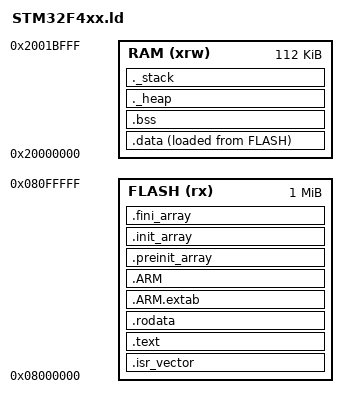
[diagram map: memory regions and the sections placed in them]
/* STM32F4xx Linker Script
 * Target: STM32F407VGTx
 * Flash: 1MB @ 0x08000000
 * SRAM1: 112KB @ 0x20000000
 * SRAM2: 16KB  @ 0x2001C000
 */

/* Entry Point */
ENTRY(Reset_Handler)

/* Highest address of the user mode stack */
_estack = 0x2001C000;    /* end of SRAM1 */

/* Minimum required sizes */
_Min_Heap_Size  = 0x200;   /* 512 bytes */
_Min_Stack_Size = 0x400;   /* 1024 bytes */

/* Memory Areas */
MEMORY
{
  FLASH (rx)  : ORIGIN = 0x08000000, LENGTH = 1024K
  RAM   (xrw) : ORIGIN = 0x20000000, LENGTH = 112K
}

SECTIONS
{
  /* Vector table at start of Flash */
  .isr_vector :
  {
    . = ALIGN(4);
    KEEP(*(.isr_vector))
    . = ALIGN(4);
  } >FLASH

  /* Code and read-only data */
  .text :
  {
    . = ALIGN(4);
    *(.text)
    *(.text*)
    *(.glue_7)
    *(.glue_7t)
    *(.eh_frame)
    KEEP(*(.init))
    KEEP(*(.fini))
    . = ALIGN(4);
    _etext = .;
  } >FLASH

  /* Read-only data */
  .rodata :
  {
    . = ALIGN(4);
    *(.rodata)
    *(.rodata*)
    . = ALIGN(4);
  } >FLASH

  /* ARM exception table */
  .ARM.extab :
  {
    *(.ARM.extab* .gnu.linkonce.armextab.*)
  } >FLASH

  .ARM :
  {
    __exidx_start = .;
    *(.ARM.exidx*)
    __exidx_end = .;
  } >FLASH

  /* Init/fini arrays */
  .preinit_array :
  {
    PROVIDE_HIDDEN(__preinit_array_start = .);
    KEEP(*(.preinit_array*))
    PROVIDE_HIDDEN(__preinit_array_end = .);
  } >FLASH

  .init_array :
  {
    PROVIDE_HIDDEN(__init_array_start = .);
    KEEP(*(SORT(.init_array.*)))
    KEEP(*(.init_array*))
    PROVIDE_HIDDEN(__init_array_end = .);
  } >FLASH

  .fini_array :
  {
    PROVIDE_HIDDEN(__fini_array_start = .);
    KEEP(*(SORT(.fini_array.*)))
    KEEP(*(.fini_array*))
    PROVIDE_HIDDEN(__fini_array_end = .);
  } >FLASH

  /* Initialized data — copied from Flash to RAM at startup */
  _sidata = LOADADDR(.data);
  .data :
  {
    . = ALIGN(4);
    _sdata = .;
    *(.data)
    *(.data*)
    . = ALIGN(4);
    _edata = .;
  } >RAM AT> FLASH

  /* Zero-initialized data */
  . = ALIGN(4);
  .bss :
  {
    . = ALIGN(4);
    _sbss = .;
    __bss_start__ = _sbss;
    *(.bss)
    *(.bss*)
    *(COMMON)
    . = ALIGN(4);
    _ebss = .;
    __bss_end__ = _ebss;
  } >RAM

  /* User heap */
  ._heap :
  {
    . = ALIGN(8);
    __heap_start = .;
    . = . + _Min_Heap_Size;
    . = ALIGN(8);
    __heap_end = .;
  } >RAM

  /* User stack — EXPLICIT SECTION */
  ._stack :
  {
    . = ALIGN(8);
    __stack_start = .;
    . = . + _Min_Stack_Size;
    . = ALIGN(8);
    __stack_end = .;
  } >RAM

  PROVIDE(__stack = .);

  /* Discard ARM unwinding info */
  /DISCARD/ :
  {
    libc.a(*)
    libm.a(*)
    libgcc.a(*)
  }

  .ARM.attributes 0 :
  {
    *(.ARM.attributes)
  }
}
